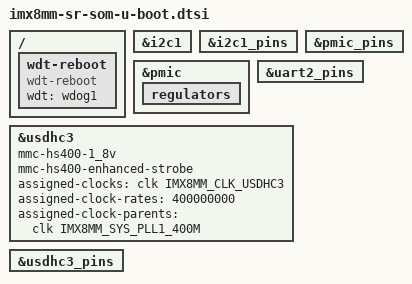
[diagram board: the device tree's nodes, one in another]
// SPDX-License-Identifier: GPL-2.0+
/*
 * Copyright 2025 Josua Mayer <josua@solid-run.com>
 */

#include "imx8mm-u-boot.dtsi"

/ {
	wdt-reboot {
		compatible = "wdt-reboot";
		wdt = <&wdog1>;
		bootph-pre-ram;
	};
};

&i2c1 {
	bootph-pre-ram;
};

&i2c1_pins {
	bootph-pre-ram;
};

&pmic {
	bootph-pre-ram;

	regulators {
		bootph-pre-ram;
	};
};

&pmic_pins {
	bootph-pre-ram;
};

&uart2_pins {
	bootph-pre-ram;
};

&usdhc3 {
	bootph-pre-ram;
	mmc-hs400-1_8v;
	mmc-hs400-enhanced-strobe;
	assigned-clocks = <&clk IMX8MM_CLK_USDHC3>;
	assigned-clock-rates = <400000000>;
	assigned-clock-parents = <&clk IMX8MM_SYS_PLL1_400M>;
};

&usdhc3_pins {
	bootph-pre-ram;
};
